AUTOSAR XML (schema 4-2-2)
package /Components
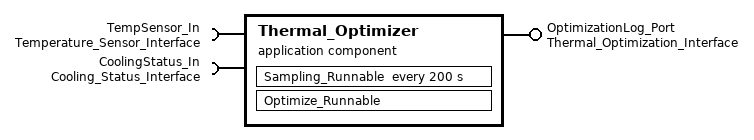
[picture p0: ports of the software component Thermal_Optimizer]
  application sw component type Thermal_Optimizer
    provide port OptimizationLog_Port: provided-interface=Thermal_Optimization_Interface
    provide/require port PumpClient_Port: provided-required-interface=PumpControl_Interface
    provide/require port ValveClient_Port: provided-required-interface=ValveControl_Interface
    require port TempSensor_In: required-interface=Temperature_Sensor_Interface
    require port CoolingStatus_In: required-interface=Cooling_Status_Interface
    behavior Thermal_Optimizer_Behavior
      internal trigger occurred event HighLoad_Trigger: start-on-event=Sampling_Runnable, event-source=HighLoadTrigger
      timing event Optimizer_Cycle_200ms: start-on-event=Sampling_Runnable, period=200
      runnable Optimize_Runnable: minimum-start-interval=200, symbol=Thermal_Optimizer.Optimize_Runnable
        data-receive-point-by-values:
          access Recv_TemperatureArray: accessed-variable={autosar-variable-in-impl-datatype={port-prototype=TempSensor_In, target-data-prototype=TemperatureArray}, autosar-variable=TempSensor_In.TemperatureArray[12]}
          access Recv_CoolingStatus: accessed-variable={autosar-variable-in-impl-datatype={port-prototype=CoolingStatus_In, target-data-prototype=CoolingStatus}, autosar-variable=CoolingStatus_In.CoolingStatus}
        data-send-points:
          access Send_OptimizationPlan: accessed-variable={autosar-variable-in-impl-datatype={port-prototype=OptimizationLog_Port, target-data-prototype=OptimizationPlan}, autosar-variable=OptimizationLog_Port.OptimizationPlan}
        sync call Call_PumpController: called-from-within-exclusive-area=OptimizeEA, operation=PumpClient_Port.SetPump, timeout=150
        sync call Call_ValveController: called-from-within-exclusive-area=OptimizeEA, operation=ValveClient_Port.SetValve, timeout=150
